VERSION ""

NS_ :

BS_:

BU_: Engine Gateway

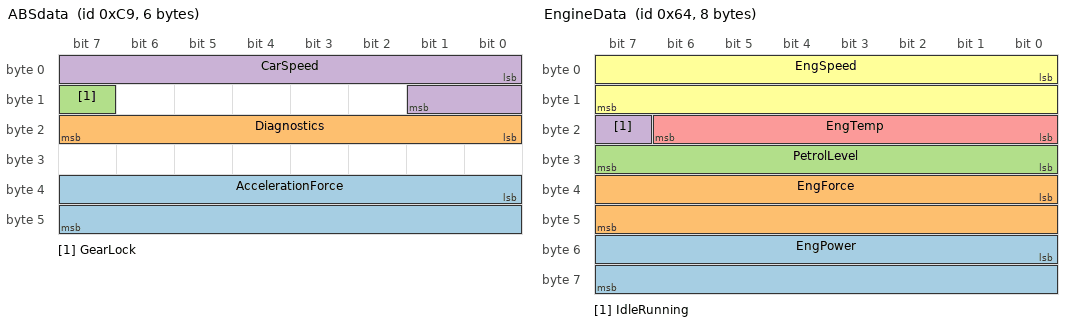
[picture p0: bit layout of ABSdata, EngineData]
BO_ 201 ABSdata: 6 Engine
 SG_ AccelerationForce : 32|16@1+ (1.0,-10000.0) [-10000.0|55535.0] "N" Vector__XXX
 SG_ Diagnostics : 16|8@1+ (1,0) [0|0] "" Vector__XXX
 SG_ GearLock : 15|1@1+ (1,0) [0|0] "" Vector__XXX
 SG_ CarSpeed : 0|10@1+ (1,0) [0|0] "mph" Vector__XXX

BO_ 512 Diag_Request: 8 Vector__XXX

BO_ 1024 Diag_Response: 8 Vector__XXX

BO_ 1537 DiagRequest_Motor: 8 Gateway
 SG_ DiagRequest : 0|64@1+ (1,0) [0|0] "" Vector__XXX

BO_ 1544 DiagResponse_Motor: 8 Engine
 SG_ DiagResponse : 0|64@1+ (1,0) [0|0] "" Vector__XXX

BO_ 100 EngineData: 8 Engine
 SG_ EngPower : 48|16@1+ (0.01,0.0) [0.0|655.35] "kW" Vector__XXX
 SG_ EngForce : 32|16@1+ (1.0,0.0) [0.0|65535.0] "N" Vector__XXX
 SG_ PetrolLevel : 24|8@1+ (1.0,0.0) [0.0|255.0] "l" Vector__XXX
 SG_ IdleRunning : 23|1@1+ (1,0) [0|0] "" Vector__XXX
 SG_ EngTemp : 16|7@1+ (1.0,0.0) [0.0|127.0] "degC" Vector__XXX
 SG_ EngSpeed : 0|16@1+ (1.0,0.0) [0.0|65535.0] "rpm" Vector__XXX

BO_ 102 EngineDataIEEE: 8 Engine
 SG_ EngForceIEEE : 32|32@1+ (1.0,0.0) [0.0|4294967295.0] "N" Vector__XXX
 SG_ EngSpeedIEEE : 0|32@1+ (1.0,0.0) [0.0|4294967295.0] "rpm" Vector__XXX

BO_ 101 EngineStatus: 1 Engine
 SG_ ErrorCode : 2|6@1+ (1,0) [0|0] "" Vector__XXX
 SG_ Status : 0|2@1+ (1,0) [0|0] "" Vector__XXX

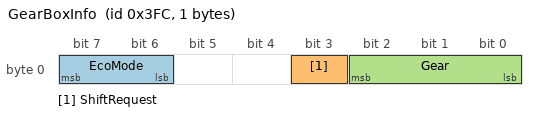
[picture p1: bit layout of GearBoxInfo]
BO_ 1020 GearBoxInfo: 1 Engine
 SG_ EcoMode : 6|2@1+ (1,0) [0|0] ""  Gateway
 SG_ ShiftRequest : 3|1@1+ (1,0) [0|0] ""  Gateway
 SG_ Gear : 0|3@1+ (1,0) [0|0] ""  Gateway

BO_ 103 Ignition_Info: 2 Gateway
 SG_ StarterKey : 0|1@1+ (1,0) [0|0] ""  Engine

BO_ 1307 NM_Engine: 4 Engine

BO_ 1306 NM_Gateway_PowerTrain: 4 Gateway

CM_ "CAN communication matrix for body electronics*******************************************************implemented: turn lights, warning lights, windows";
BA_DEF_ BO_  "GenMsgCycleTime" INT 0 65535;
BA_DEF_DEF_  "GenMsgCycleTime" 0;
BA_ "GenMsgCycleTime" BO_ 201 50;
BA_ "GenMsgCycleTime" BO_ 100 50;
BA_ "GenMsgCycleTime" BO_ 102 50;
BA_ "GenMsgCycleTime" BO_ 1020 50;
BA_ "GenMsgCycleTime" BO_ 103 20;
